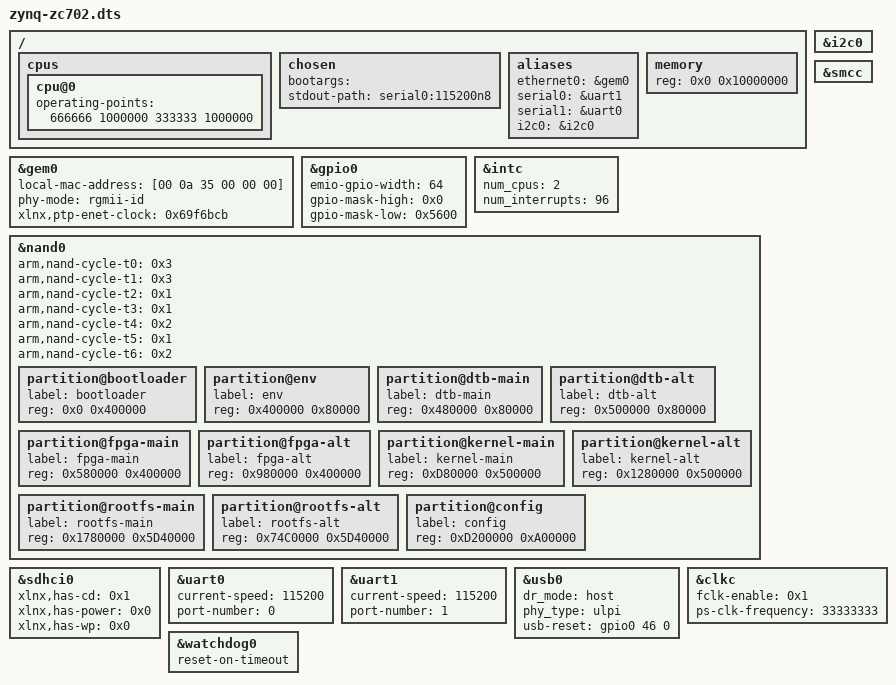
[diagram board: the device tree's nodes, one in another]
/*
 * CAUTION: This file is automatically generated by Xilinx.
 * Version:  
 * Today is: Thu Mar 22 09:50:10 2018
*/


/dts-v1/;
/include/ "zynq-7000.dtsi"

/ {
	cpus {
		cpu@0 {
			operating-points = <666666 1000000 333333 1000000>;
		};
	};

	chosen {
	        bootargs = "";
		stdout-path = "serial0:115200n8";
	};

	aliases {
		ethernet0 = &gem0;
		serial0 = &uart1;
		serial1 = &uart0;
		i2c0 = &i2c0;
	};
	memory {
		device_type = "memory";
		reg = <0x0 0x10000000>;
	};
};
&gem0 {
	local-mac-address = [00 0a 35 00 00 00];
	phy-mode = "rgmii-id";
	status = "okay";
	xlnx,ptp-enet-clock = <0x69f6bcb>;
};
&gpio0 {
	emio-gpio-width = <64>;
	gpio-mask-high = <0x0>;
	gpio-mask-low = <0x5600>;
};
&i2c0 {
	status = "okay";
};
&intc {
	num_cpus = <2>;
	num_interrupts = <96>;
};
&nand0 {
	arm,nand-cycle-t0 = <0x3>;
	arm,nand-cycle-t1 = <0x3>;
	arm,nand-cycle-t2 = <0x1>;
	arm,nand-cycle-t3 = <0x1>;
	arm,nand-cycle-t4 = <0x2>;
	arm,nand-cycle-t5 = <0x1>;
	arm,nand-cycle-t6 = <0x2>;
	status = "okay";
	partition@bootloader {
		label = "bootloader";
		reg = <0x0 0x400000>;
	};
	partition@env {
		label = "env";
		reg = <0x400000 0x80000>;
	};
	partition@dtb-main {
		label = "dtb-main";
		reg = <0x480000 0x80000>;
	};
	partition@dtb-alt {
		label = "dtb-alt";
		reg = <0x500000 0x80000>;
	};
	partition@fpga-main {
		label = "fpga-main";
		reg = <0x580000 0x400000>;
	};
	partition@fpga-alt {
		label = "fpga-alt";
		reg = <0x980000 0x400000>;
	};
	partition@kernel-main {
		label = "kernel-main";
		reg = <0xD80000 0x500000>;
	};
	partition@kernel-alt {
		label = "kernel-alt";
		reg = <0x1280000 0x500000>;
	};
	partition@rootfs-main {
		label = "rootfs-main";
		reg = <0x1780000 0x5D40000>;
	};
	partition@rootfs-alt {
		label = "rootfs-alt";
		reg = <0x74C0000 0x5D40000>;
	};
	partition@config {
		label = "config";
		reg = <0xD200000 0xA00000>;
	};
};
&sdhci0 {
	status = "okay";
	xlnx,has-cd = <0x1>;
	xlnx,has-power = <0x0>;
	xlnx,has-wp = <0x0>;
};
&smcc {
	status = "okay";
};
&uart0 {
	current-speed = <115200>;
	device_type = "serial";
	port-number = <0>;
	status = "okay";
};
&uart1 {
	current-speed = <115200>;
	device_type = "serial";
	port-number = <1>;
	status = "okay";
};
&usb0 {
	dr_mode = "host";
	phy_type = "ulpi";
	status = "okay";
	usb-reset = <&gpio0 46 0>;
};
&clkc {
	fclk-enable = <0x1>;
	ps-clk-frequency = <33333333>;
};
&watchdog0 {
	status = "okay";
	reset-on-timeout;
};
